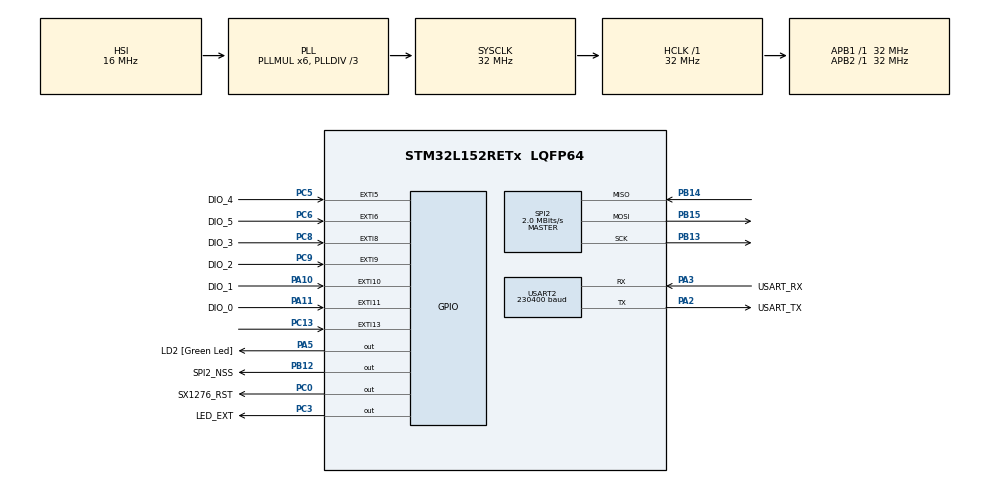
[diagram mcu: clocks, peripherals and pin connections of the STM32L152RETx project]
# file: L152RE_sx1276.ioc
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Mcu.Family=STM32L1
PH0-OSC_IN.Signal=RCC_OSC_IN
SPI2.VirtualType=VM_MASTER
PA14.GPIO_Label=TCK
PC0.GPIO_Label=SX1276_RST
PC6.GPIO_Label=DIO_5
VP_RTC_VS_RTC_Activate.Mode=RTC_Enabled
PB13.Signal=SPI2_SCK
PB15.Signal=SPI2_MOSI
VP_RTC_VS_RTC_Alarm_A_Intern.Mode=Alarm A
RCC.SYSCLKSource=RCC_SYSCLKSOURCE_PLLCLK
ProjectManager.StackSize=0x400
RCC.PLLDIV=RCC_PLL_DIV3
RCC.HCLKFreq_Value=32000000
RCC.APB2TimFreq_Value=32000000
PC3.Signal=GPIO_Output
RCC.AHBFreq_Value=32000000
SPI2.BaudRatePrescaler=SPI_BAUDRATEPRESCALER_16
PH0-OSC_IN.Mode=HSE-External-Clock-Source
NVIC.EXTI15_10_IRQn=true\:5\:0\:true\:false\:true\:true\:true
RCC.HSE_VALUE=8000000
PC13-WKUP2.Signal=GPXTI13
RCC.PLLMUL=RCC_PLL_MUL6
PB12.GPIO_Label=SPI2_NSS
PC14-OSC32_IN.Mode=LSE-External-Oscillator
RCC.RTCClockSelectionVirtual=RCC_RTCCLKSOURCE_LSE
PA14.Mode=Serial_Wire
PB14.Mode=Full_Duplex_Master
NVIC.TIM2_IRQn=true\:0\:0\:false\:false\:true\:false\:true
PA10.GPIO_Label=DIO_1
SPI2.CalculateBaudRate=2.0 MBits/s
Mcu.Package=LQFP64
VP_SYS_VS_tim2.Mode=TIM2
NVIC.TimeBase=TIM2_IRQn
SPI2.Mode=SPI_MODE_MASTER
USART2.VirtualMode=VM_ASYNC
RCC.USBOutput=48000000
PA2.GPIO_Label=USART_TX
NVIC.TimeBaseIP=TIM2
PA10.Signal=GPXTI10
VP_RTC_VS_RTC_Calendar.Mode=RTC_Calendar
RCC.APB1TimFreq_Value=32000000
SPI2.Direction=SPI_DIRECTION_2LINES
PC5.Signal=GPXTI5
PB13.Mode=Full_Duplex_Master
PA3.Signal=USART2_RX
PB3.GPIO_Label=SWO
RCC.MSI_VALUE=2097000
PC15-OSC32_OUT.Mode=LSE-External-Oscillator
PC9.GPIO_Label=DIO_2
PC8.Signal=GPXTI8
PC6.Signal=GPXTI6
PA11.GPIO_Label=DIO_0
PC0.Signal=GPIO_Output
PC14-OSC32_IN.Signal=RCC_OSC32_IN
NVIC.USART2_IRQn=true\:5\:0\:true\:false\:true\:true\:true
USART2.BaudRate=230400
PC8.GPIO_Label=DIO_3
PA3.Mode=Asynchronous
PA13.Signal=SYS_JTMS-SWDIO
ProjectManager.TargetToolchain=STM32CubeIDE
PC15-OSC32_OUT.Signal=RCC_OSC32_OUT
PB14.Signal=SPI2_MISO
PA5.Signal=GPIO_Output
board=NUCLEO-L152RE
RCC.VCOOutputFreq_Value=96000000
PB15.Mode=Full_Duplex_Master
RCC.APB2Freq_Value=32000000
PH1-OSC_OUT.Signal=RCC_OSC_OUT
PA13.Mode=Serial_Wire
NVIC.RTC_Alarm_IRQn=true\:5\:0\:true\:false\:true\:true\:true
Mcu.Name=STM32L152RETx
RTC.Alarm-Alarm\ A=RTC_ALARM_A
PA2.Signal=USART2_TX
PA13.GPIO_Label=TMS
RCC.48MHZClocksFreq_Value=48000000
PB3.Signal=SYS_JTDO-TRACESWO
RCC.SYSCLKFreq_VALUE=32000000
PA5.GPIO_Label=LD2 [Green Led]
PC5.GPIO_Label=DIO_4
PA11.Signal=GPXTI11
NVIC.EXTI9_5_IRQn=true\:5\:0\:true\:false\:true\:true\:true
PA14.Signal=SYS_JTCK-SWCLK
ProjectManager.HeapSize=0x200
RCC.HSI_VALUE=16000000
NVIC.PriorityGroup=NVIC_PRIORITYGROUP_4
PA2.Mode=Asynchronous
PC3.GPIO_Label=LED_EXT
PC9.Signal=GPXTI9
RCC.APB1Freq_Value=32000000
PB12.Signal=GPIO_Output
PA3.GPIO_Label=USART_RX

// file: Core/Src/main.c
/* USER CODE BEGIN Header */
/* USER CODE END Header */
#include "main.h"
#include "rtc.h"
#include "spi.h"
#include "usart.h"
#include "gpio.h"

/* USER CODE BEGIN Includes */
#include "rf-test.h"
//#include "continuous_wave.h"
/* USER CODE END Includes */

void SystemClock_Config(void);

int main(void)
{

  /* MCU Configuration--------------------------------------------------------*/

  /* Reset of all peripherals, Initializes the Flash interface and the Systick. */
  HAL_Init();

  /* Configure the system clock */
  SystemClock_Config();

  /* Initialize all configured peripherals */
  MX_GPIO_Init();
  MX_USART2_UART_Init();
  MX_SPI2_Init();
  MX_RTC_Init();
  /* USER CODE BEGIN 2 */
  struct InputParametrsTX_s iparam;
  struct BER_TX_s berParam;
  berParam.len = BARKER_11;
  struct PER_TX_s perParam = { 20 , 20 };
  iparam.pBER = &berParam;
  iparam.pPER = &perParam;
  iparam.mode = BER;
  Measurements( &iparam );

//  ping_pong_rf();
//  continuos_wave();
  /* USER CODE END 2 */

  /* Infinite loop */
  /* USER CODE BEGIN WHILE */
  while(1);
    /* USER CODE END WHILE */

}

void SystemClock_Config(void)
{
  RCC_OscInitTypeDef RCC_OscInitStruct = {0};
  RCC_ClkInitTypeDef RCC_ClkInitStruct = {0};
  RCC_PeriphCLKInitTypeDef PeriphClkInit = {0};

  /** Configure the main internal regulator output voltage
  */
  __HAL_PWR_VOLTAGESCALING_CONFIG(PWR_REGULATOR_VOLTAGE_SCALE1);
  /** Initializes the RCC Oscillators according to the specified parameters
  * in the RCC_OscInitTypeDef structure.
  */
  RCC_OscInitStruct.OscillatorType = RCC_OSCILLATORTYPE_HSI|RCC_OSCILLATORTYPE_LSE;
  RCC_OscInitStruct.LSEState = RCC_LSE_ON;
  RCC_OscInitStruct.HSIState = RCC_HSI_ON;
  RCC_OscInitStruct.HSICalibrationValue = RCC_HSICALIBRATION_DEFAULT;
  RCC_OscInitStruct.PLL.PLLState = RCC_PLL_ON;
  RCC_OscInitStruct.PLL.PLLSource = RCC_PLLSOURCE_HSI;
  RCC_OscInitStruct.PLL.PLLMUL = RCC_PLL_MUL6;
  RCC_OscInitStruct.PLL.PLLDIV = RCC_PLL_DIV3;
  if (HAL_RCC_OscConfig(&RCC_OscInitStruct) != HAL_OK)
  {
    Error_Handler();
  }
  /** Initializes the CPU, AHB and APB buses clocks
  */
  RCC_ClkInitStruct.ClockType = RCC_CLOCKTYPE_HCLK|RCC_CLOCKTYPE_SYSCLK
                              |RCC_CLOCKTYPE_PCLK1|RCC_CLOCKTYPE_PCLK2;
  RCC_ClkInitStruct.SYSCLKSource = RCC_SYSCLKSOURCE_PLLCLK;
  RCC_ClkInitStruct.AHBCLKDivider = RCC_SYSCLK_DIV1;
  RCC_ClkInitStruct.APB1CLKDivider = RCC_HCLK_DIV1;
  RCC_ClkInitStruct.APB2CLKDivider = RCC_HCLK_DIV1;

  if (HAL_RCC_ClockConfig(&RCC_ClkInitStruct, FLASH_LATENCY_1) != HAL_OK)
  {
    Error_Handler();
  }
  PeriphClkInit.PeriphClockSelection = RCC_PERIPHCLK_RTC;
  PeriphClkInit.RTCClockSelection = RCC_RTCCLKSOURCE_LSE;
  if (HAL_RCCEx_PeriphCLKConfig(&PeriphClkInit) != HAL_OK)
  {
    Error_Handler();
  }
}

 /**
  * @brief  Period elapsed callback in non blocking mode
  * @note   This function is called  when TIM2 interrupt took place, inside
  * HAL_TIM_IRQHandler(). It makes a direct call to HAL_IncTick() to increment
  * a global variable "uwTick" used as application time base.
  * @param  htim : TIM handle
  * @retval None
  */
void HAL_TIM_PeriodElapsedCallback(TIM_HandleTypeDef *htim)
{
  if (htim->Instance == TIM2) {
    HAL_IncTick();
  }
}

void Error_Handler(void)
{
}

/************************ (C) COPYRIGHT STMicroelectronics *****END OF FILE****/
